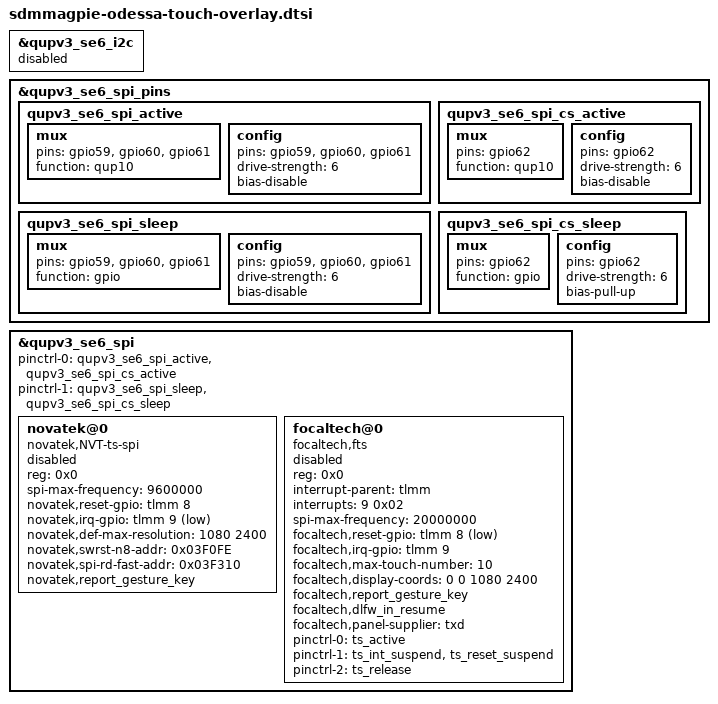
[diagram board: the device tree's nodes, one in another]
&qupv3_se6_i2c {
	status = "disabled";
};

&qupv3_se6_spi_pins {
	qupv3_se6_spi_active: qupv3_se6_spi_active {
		mux {
			pins = "gpio59", "gpio60", "gpio61";
			function = "qup10";
		};

		config {
			pins = "gpio59", "gpio60", "gpio61";
			drive-strength = <6>;
			bias-disable;
		};
	};

	qupv3_se6_spi_sleep: qupv3_se6_spi_sleep {
		mux {
			pins = "gpio59", "gpio60", "gpio61";
			function = "gpio";
		};

		config {
			pins = "gpio59", "gpio60", "gpio61";
			drive-strength = <6>;
			bias-disable;
		};
	};

	qupv3_se6_spi_cs_active: qupv3_se6_spi_cs_active {
		mux {
			pins = "gpio62";
			function = "qup10";
		};

		config {
			pins = "gpio62";
			drive-strength = <6>;
			bias-disable;
		};
	};

	qupv3_se6_spi_cs_sleep: qupv3_se6_spi_cs_sleep {
		mux {
			pins = "gpio62";
			function = "gpio";
		};

		config {
			pins = "gpio62";
			drive-strength = <6>;
			bias-pull-up;
		};
	};
};

&qupv3_se6_spi {
	status = "ok";
	pinctrl-0 = <&qupv3_se6_spi_active &qupv3_se6_spi_cs_active>;
	pinctrl-1 = <&qupv3_se6_spi_sleep &qupv3_se6_spi_cs_sleep>;
	novatek@0 {
		compatible = "novatek,NVT-ts-spi";
		reg = <0x0>;
		spi-max-frequency = <9600000>;  /* 4800000,9600000,15000000,19200000 */
		novatek,reset-gpio = <&tlmm 8 0x00>;
		novatek,irq-gpio = <&tlmm 9 0x2001>;
		novatek,def-max-resolution = <1080 2400>;
		novatek,swrst-n8-addr = <0x03F0FE>;
		novatek,spi-rd-fast-addr = <0x03F310>;
		novatek,report_gesture_key;
		status = "/chosen", "mmi,panel_name", "auo_nt36675_fhd_vid";
	};

	focaltech@0 {
		compatible = "focaltech,fts";
		reg = <0x0>;
		interrupt-parent = <&tlmm>;
		interrupts = <9 0x02>;
		spi-max-frequency=<20000000>;
		focaltech,reset-gpio = <&tlmm 8 0x01>;
		focaltech,irq-gpio = <&tlmm 9 0x02>;
		focaltech,max-touch-number = <10>;
		focaltech,display-coords =  <0 0 1080 2400>;
		focaltech,report_gesture_key;
		focaltech,dlfw_in_resume;
		focaltech,panel-supplier = "txd";
		pinctrl-names = "pmx_ts_active","pmx_ts_suspend","pmx_ts_release";
		pinctrl-0 = <&ts_active>;
		pinctrl-1 = <&ts_int_suspend &ts_reset_suspend>;
		pinctrl-2 = <&ts_release>;
		status = "/chosen", "mmi,panel_name", "txd_ft8756_fhd_vid";
	};
};

